# GD32EPRT register map
File version: 1.0
CPU: CM33 r0p4, little endian, MPU, FPU, 4 interrupt priority bits
Registers are 32-bit, read-write, reset 0x0 unless marked. A register's access mark holds for its fields unless they carry their own. Offsets are from the block's base; [hi:lo] are bit positions; {n}, {i} and the like mark numbered series; 'fields as' and 'values as' point back to an identical list.

## DBG — Debug support
Base 0xE0044000
0x00 ID ro — ID code register
  [31:0] ID_CODE — DBG ID code register
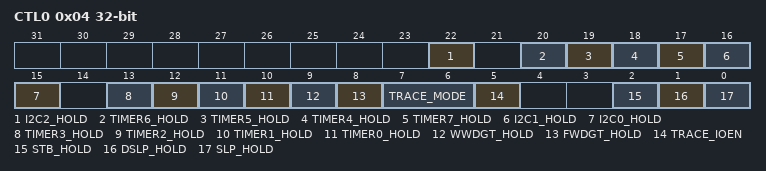
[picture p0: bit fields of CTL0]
0x04 CTL0 — Control register 0
  [22] I2C2_HOLD — I2C2 hold bit
  [20] TIMER6_HOLD — TIMER 6 hold bit
  [19] TIMER5_HOLD — TIMER 5 hold bit
  [18] TIMER4_HOLD
  [17] TIMER7_HOLD
  [16] I2C1_HOLD — I2C1 hold bit
  [15] I2C0_HOLD — I2C0 hold bit
  [13] TIMER3_HOLD — TIMER 23 hold bit
  [12] TIMER2_HOLD — TIMER 2 hold bit
  [11] TIMER1_HOLD — TIMER 1 hold bit
  [10] TIMER0_HOLD — TIMER 0 hold bit
  [9] WWDGT_HOLD — WWDGT hold bit
  [8] FWDGT_HOLD — FWDGT hold bit
  [7:6] TRACE_MODE — Trace pin allocation mode
  [5] TRACE_IOEN — Trace pin allocation enable
  [2] STB_HOLD — Standby mode hold register
  [1] DSLP_HOLD — Deep-sleep mode hold register
  [0] SLP_HOLD — Sleep mode hold register

## DMA0 — DMA controller
Base 0x40020000
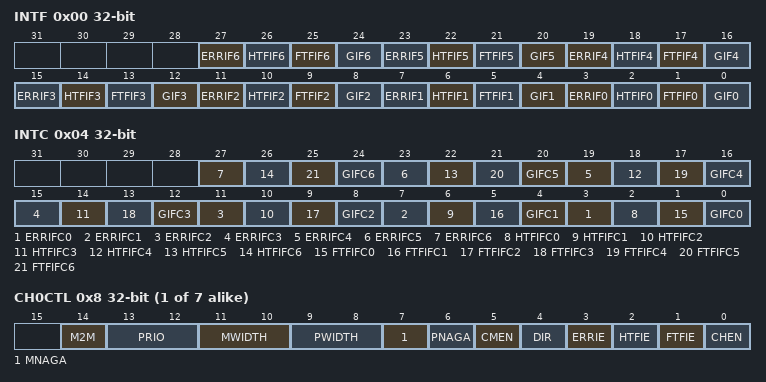
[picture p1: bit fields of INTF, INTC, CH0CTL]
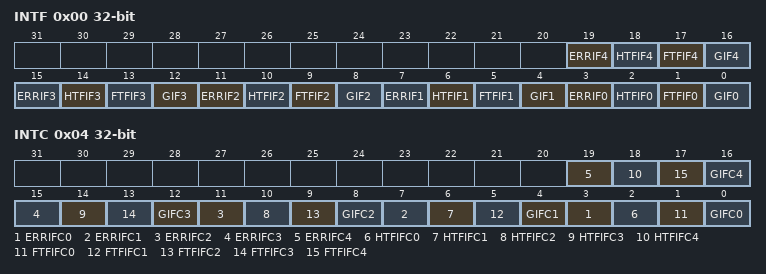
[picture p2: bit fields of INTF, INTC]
0x00 INTF ro — Interrupt flag register
  [4n+3] ERRIF{n} (n=0..6) — Error flag of channel {n}
  [4n+2] HTFIF{n} (n=0..6) — Half transfer finish flag of channel {n}
  [4n+1] FTFIF{n} (n=0..6) — Full Transfer finish flag of channe {n}
  [4n] GIF{n} (n=0..6) — Global interrupt flag of channel {n}
0x04 INTC wo — Interrupt flag clear register
  [4n+3] ERRIFC{n} (n=0..6) — Clear bit for error flag of channel {n}
  [4n+2] HTFIFC{n} (n=0..6) — Clear bit for half transfer finish flag of channel {n}
  [4n+1] FTFIFC{n} (n=0..6) — Clear bit for full transfer finish flag of channel {n}
  [4n] GIFC{n} (n=0..6) — Clear global interrupt flag of channel {n}
{0x8+0x14*i} CH{i}CTL (i=0..6) — Channel {i} control register
  [14] M2M — Memory to Memory Mode
  [13:12] PRIO — Priority level
  [11:10] MWIDTH — Transfer data size of memory
  [9:8] PWIDTH — Transfer data size of peripheral
  [7] MNAGA — Next address generation algorithm of memory
  [6] PNAGA — Next address generation algorithm of peripheral
  [5] CMEN — Circular mode enable
  [4] DIR — Transfer direction
  [3] ERRIE — Enable bit for channel error interrupt
  [2] HTFIE — Enable bit for channel half transfer finish interrupt
  [1] FTFIE — Enable bit for channel full transfer finish interrupt
  [0] CHEN — Channel enable
{0xC+0x14*i} CH{i}CNT (i=0..6) — Channel {i} counter register
  [15:0] CNT — Transfer counter
{0x10+0x14*i} CH{i}PADDR (i=0..6) — Channel {i} peripheral base address register
  [31:0] PADDR — Peripheral base address
{0x14+0x14*i} CH{i}MADDR (i=0..6) — Channel {i} memory base address register
  [31:0] MADDR — Memory base address

## DMA1 — DMA controller
Base 0x40020400
Registers as DMA0, without CH5CTL, CH5CNT, CH5PADDR, CH5MADDR, CH6CTL, CH6CNT, CH6PADDR, CH6MADDR; these are added or differ:
0x00 INTF ro — Interrupt flag register
  [4n+3] ERRIF{n} (n=0..4) — Error flag of channel {n}
  [4n+2] HTFIF{n} (n=0..4) — Half transfer finish flag of channel {n}
  [4n+1] FTFIF{n} (n=0..4) — Full Transfer finish flag of channe {n}
  [4n] GIF{n} (n=0..4) — Global interrupt flag of channel {n}
0x04 INTC wo — Interrupt flag clear register
  [4n+3] ERRIFC{n} (n=0..4) — Clear bit for error flag of channel {n}
  [4n+2] HTFIFC{n} (n=0..4) — Clear bit for half transfer finish flag of channel {n}
  [4n+1] FTFIFC{n} (n=0..4) — Clear bit for full transfer finish flag of channel {n}
  [4n] GIFC{n} (n=0..4) — Clear global interrupt flag of channel {n}

## EXMC — External memory controller
Base 0xA0000000
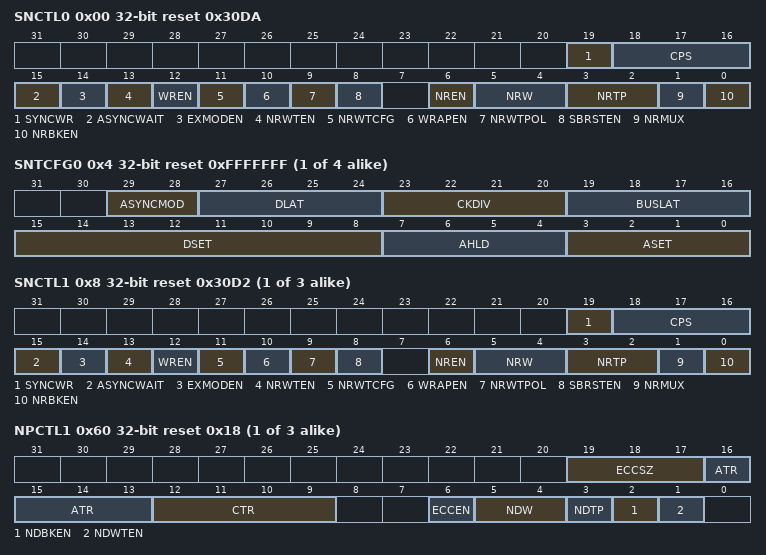
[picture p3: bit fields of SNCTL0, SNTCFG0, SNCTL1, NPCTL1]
0x00 SNCTL0 reset 0x30DA — SRAM/NOR flash control register 0
  [19] SYNCWR — Synchronous write
  [18:16] CPS — CRAM page size
  [15] ASYNCWAIT — Asynchronous wait
  [14] EXMODEN — Extended mode enable
  [13] NRWTEN — NWAIT signal enable
  [12] WREN — Write enable
  [11] NRWTCFG — NWAIT signal configuration, only work in synchronous mode
  [10] WRAPEN — Wrapped burst mode enable
  [9] NRWTPOL — NWAIT signal polarity
  [8] SBRSTEN — Synchronous burst enable
  [6] NREN — NOR Flash access enable
  [5:4] NRW — NOR bank memory data bus width
  [3:2] NRTP — NOR bank memory type
  [1] NRMUX — NOR bank memory address/data multiplexing
  [0] NRBKEN — NOR bank enable
{0x4+8i} SNTCFG{i} reset 0xFFFFFFF (i=0..3) — SRAM/NOR flash timing configuration register {i}
  [29:28] ASYNCMOD — Asynchronous access mode
  [27:24] DLAT — Data latency for NOR Flash
  [23:20] CKDIV — Synchronous clock divide ratio
  [19:16] BUSLAT — Bus latency
  [15:8] DSET — Data setup time
  [7:4] AHLD — Address hold time
  [3:0] ASET — Address setup time
{0x0+8i} SNCTL{i} reset 0x30D2 (i=1..3) — SRAM/NOR flash control register {i}
  fields as SNCTL0
{0x40+0x20*i} NPCTL{i} reset 0x18 (i=1..3) — NAND flash/PC card control register {i}
  [19:17] ECCSZ — ECC size
  [16:13] ATR — ALE to RE delay
  [12:9] CTR — CLE to RE delay
  [6] ECCEN — ECC enable
  [5:4] NDW — NAND bank memory data bus width
  [3] NDTP — NAND bank memory type
  [2] NDBKEN — NAND bank enable
  [1] NDWTEN — Wait feature enable
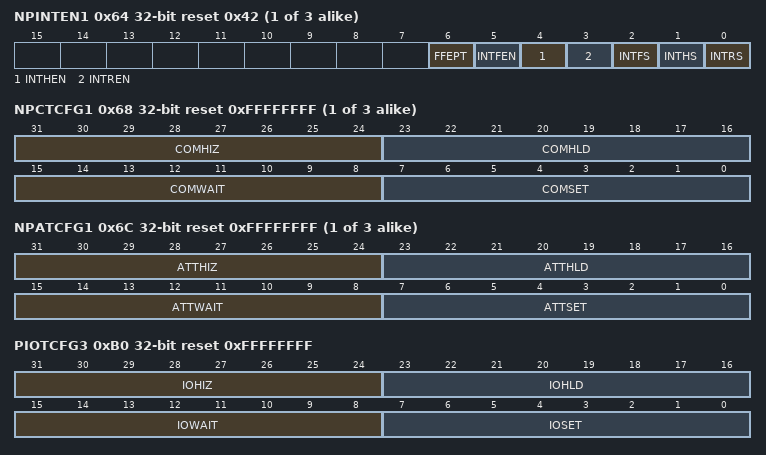
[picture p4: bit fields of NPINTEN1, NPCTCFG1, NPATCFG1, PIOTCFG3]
{0x44+0x20*i} NPINTEN{i} reset 0x42 (i=1..3) — NAND flash/PC card interrupt enable register {i}
  [6] FFEPT — FIFO empty flag
  [5] INTFEN — Interrupt falling edge detection enable
  [4] INTHEN — Interrupt high-level detection enable
  [3] INTREN — Interrupt rising edge detection enable bit
  [2] INTFS — Interrupt falling edge status
  [1] INTHS — Interrupt high-level status
  [0] INTRS — Interrupt rising edge status
{0x48+0x20*i} NPCTCFG{i} reset 0xFFFFFFFF (i=1..3) — NAND flash/PC card common space timing configuration register {i}
  [31:24] COMHIZ — Common memory data bus HiZ time
  [23:16] COMHLD — Common memory hold time
  [15:8] COMWAIT — Common memory wait time
  [7:0] COMSET — Common memory setup time
{0x4C+0x20*i} NPATCFG{i} reset 0xFFFFFFFF (i=1..3) — NAND flash/PC card attribute space timing configuration register {i}
  [31:24] ATTHIZ — Attribute memory data bus HiZ time
  [23:16] ATTHLD — Attribute memory hold time
  [15:8] ATTWAIT — Attribute memory wait time
  [7:0] ATTSET — Attribute memory setup time
0x74 NECC1 ro — NAND flash ECC register 1
  [31:0] ECC — ECC result
0x94 NECC2 ro — NAND flash ECC register 2
  [31:0] ECC — ECC result
0xB0 PIOTCFG3 reset 0xFFFFFFFF — PC card I/O space timing configuration register
  [31:24] IOHIZ — IO space data bus HiZ time
  [23:16] IOHLD — IO space hold time
  [15:8] IOWAIT — IO space wait time
  [7:0] IOSET — IO space setup time
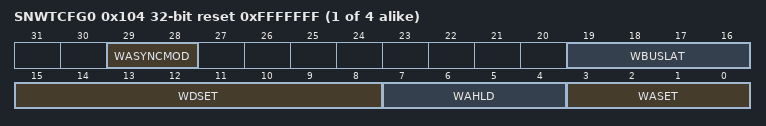
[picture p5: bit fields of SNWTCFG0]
{0x104+8i} SNWTCFG{i} reset 0xFFFFFFF (i=0..3) — SRAM/NOR flash write timing configuration register {i}
  [29:28] WASYNCMOD — Asynchronous access mode
  [19:16] WBUSLAT — Bus latency
  [15:8] WDSET — Data setup time
  [7:4] WAHLD — Address hold time
  [3:0] WASET — Address setup time
